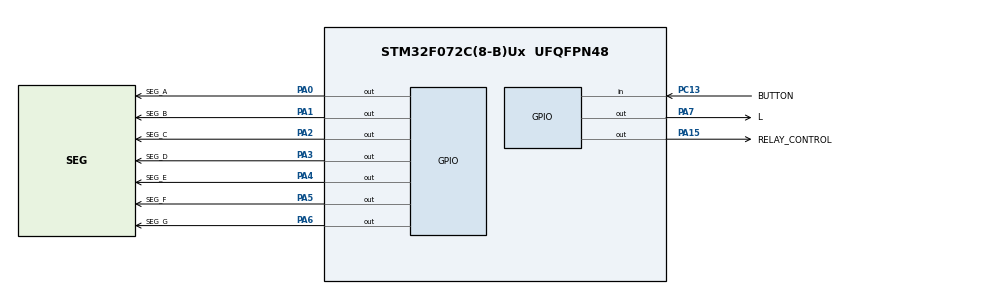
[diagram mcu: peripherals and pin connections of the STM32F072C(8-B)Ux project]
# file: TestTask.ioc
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Mcu.Family=STM32F0
Mcu.Name=STM32F072C(8-B)Ux
Mcu.Package=UFQFPN48
NVIC.TIM14_IRQn=true\:0\:0\:false\:false\:true\:true\:false\:true
NVIC.TIM6_DAC_IRQn=true\:0\:0\:false\:false\:true\:true\:false\:true
NVIC.TIM7_IRQn=true\:0\:0\:false\:false\:true\:true\:false\:true
PA0.GPIO_Label=SEG_A
PA0.Signal=GPIO_Output
PA1.GPIO_Label=SEG_B
PA1.Signal=GPIO_Output
PA13.Mode=Serial_Wire
PA13.Signal=SYS_SWDIO
PA14.Mode=Serial_Wire
PA14.Signal=SYS_SWCLK
PA15.GPIO_Label=RELAY_CONTROL
PA15.Signal=GPIO_Output
PA2.GPIO_Label=SEG_C
PA2.Signal=GPIO_Output
PA3.GPIO_Label=SEG_D
PA3.Signal=GPIO_Output
PA4.GPIO_Label=SEG_E
PA4.Signal=GPIO_Output
PA5.GPIO_Label=SEG_F
PA5.Signal=GPIO_Output
PA6.GPIO_Label=SEG_G
PA6.Signal=GPIO_Output
PA7.GPIO_Label=L
PA7.Signal=GPIO_Output
PC13.GPIO_Label=BUTTON
PC13.GPIO_PuPd=GPIO_PULLUP
PC13.Signal=GPIO_Input
ProjectManager.HeapSize=0x200
ProjectManager.StackSize=0x400
ProjectManager.TargetToolchain=MDK-ARM V5.32
RCC.AHBFreq_Value=48000000
RCC.APB1Freq_Value=48000000
RCC.APB1TimFreq_Value=48000000
RCC.HCLKFreq_Value=48000000
RCC.SYSCLKFreq_VALUE=48000000
RCC.SYSCLKSource=RCC_SYSCLKSOURCE_HSI48
TIM14.Period=1000-1
TIM14.Prescaler=48000-1
TIM6.Period=30000-1
TIM6.Prescaler=16-1
TIM7.Period=10000-1
TIM7.Prescaler=48-1
VP_TIM14_VS_ClockSourceINT.Mode=Enable_Timer
VP_TIM6_VS_ClockSourceINT.Mode=Enable_Timer
VP_TIM7_VS_ClockSourceINT.Mode=Enable_Timer
board=custom

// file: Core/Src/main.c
/* USER CODE BEGIN Header */
/**
  ******************************************************************************
  * @file           : main.c
  * @brief          : Main program body
  ******************************************************************************
  * @attention
  *
  * Copyright (c) 2026 STMicroelectronics.
  * All rights reserved.
  *
  * This software is licensed under terms that can be found in the LICENSE file
  * in the root directory of this software component.
  * If no LICENSE file comes with this software, it is provided AS-IS.
  *
  ******************************************************************************
  */
/* USER CODE END Header */
#include "main.h"
#include "tim.h"
#include "gpio.h"

/* USER CODE BEGIN Includes */
#include "timer_and_control.h"
#include "display.h"
/* USER CODE END Includes */

void SystemClock_Config(void);

int main(void)
{

  /* MCU Configuration--------------------------------------------------------*/

  /* Reset of all peripherals, Initializes the Flash interface and the Systick. */
  LL_APB1_GRP2_EnableClock(LL_APB1_GRP2_PERIPH_SYSCFG);
  LL_APB1_GRP1_EnableClock(LL_APB1_GRP1_PERIPH_PWR);

  /* SysTick_IRQn interrupt configuration */
  NVIC_SetPriority(SysTick_IRQn, 3);

  /* Configure the system clock */
  SystemClock_Config();

  /* Initialize all configured peripherals */
  MX_GPIO_Init();
  MX_TIM6_Init();
  MX_TIM7_Init();
  MX_TIM14_Init();
  /* USER CODE BEGIN 2 */
	init_timer_and_control();
	init_display();
	TIM6_Start();
	TIM7_Start();
	TIM14_Start();
  /* USER CODE END 2 */

  /* Infinite loop */
  while (1)
  {

  }
}

void SystemClock_Config(void)
{
  LL_FLASH_SetLatency(LL_FLASH_LATENCY_1);
  while(LL_FLASH_GetLatency() != LL_FLASH_LATENCY_1)
  {
  }
  LL_RCC_HSI48_Enable();

   /* Wait till HSI48 is ready */
  while(LL_RCC_HSI48_IsReady() != 1)
  {

  }
  LL_RCC_SetAHBPrescaler(LL_RCC_SYSCLK_DIV_1);
  LL_RCC_SetAPB1Prescaler(LL_RCC_APB1_DIV_1);
  LL_RCC_SetSysClkSource(LL_RCC_SYS_CLKSOURCE_HSI48);

   /* Wait till System clock is ready */
  while(LL_RCC_GetSysClkSource() != LL_RCC_SYS_CLKSOURCE_STATUS_HSI48)
  {

  }
  LL_Init1msTick(48000000);
  LL_SetSystemCoreClock(48000000);
}

void Error_Handler(void)
{
  __disable_irq();
  while (1)
  {
  }
}
